# TLE9263 register map
Vendor: Infineon; File version: 0.2
Registers are 8-bit, read-write, no defined reset value unless marked. A register's access mark holds for its fields unless they carry their own. Offsets are from the block's base; [hi:lo] are bit positions; {n}, {i} and the like mark numbered series; 'fields as' and 'values as' point back to an identical list.

## CTRL — Control
Base 0x00000000
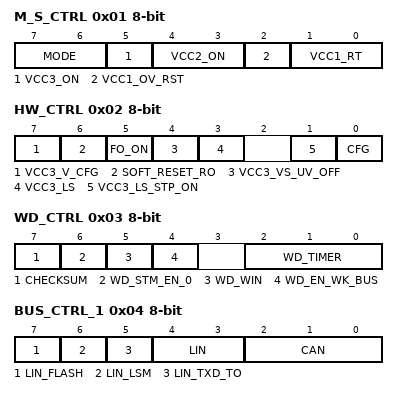
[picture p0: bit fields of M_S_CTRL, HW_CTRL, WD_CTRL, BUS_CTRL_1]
0x01 M_S_CTRL — Mode- and Supply Control
  [7:6] MODE — SBC Mode Control
    0=Normal (SBC Normal Mode); 1=Sleep (SBC Sleep Mode); 2=Stop (SBC Stop Mode); 3=Soft_Reset (SBC Reset: Soft Reset is executed (configuration of RSTN triggering in bit SOFT_RESET_RST))
  [5] VCC3_ON — VCC3 Mode Control
    0=VCC3_off; 1=VCC3_enabled (VCC3 is enabled (as independent voltage regulator))
  [4:3] VCC2_ON — VCC2 Mode Control
    0=VCC2_off; 1=Normal_Mode (VCC2 on in Normal Mode); 2=Normal_and_Stop_Mode (VCC2 on in Normal and Stop Mode); 3=VCC2 always on (except in SBC Init - if not in SBC Development Mode, SBC Restart and Fail-Safe Mode)
  [2] VCC1_OV_RST — VCC1 Over Voltage leading to Restart / Fail-Safe Mode enable
    0=off (VCC1_ OV is set in case of VCC1_OV; no SBC Restart or Fail-Safe is entered for VCC1_OV); 1=activated (VCC1_ OV is set in case of VCC1_OV; depending on the device configuration SBC Restart or SBC Fail-Safe Mode is entered (see );)
  [1:0] VCC1_RT — VCC1 Reset Threshold Control
    0=Vrt1 selected (highest threshold); 1=Vrt2 selected; 2=Vrt3 selected; 3=Vrt4 selected
0x02 HW_CTRL — Hardware Control 0
  [7] VCC3_V_CFG — VCC3 Output Voltage Configuration (if configured as independent voltage regulator)
    0=VCC3_is_same_as_VCC1 (VCC3 has same output voltage as VCC1); 1=3.3V_or_1.8V (VCC3 is configured to either 3.3V or 1.8V (depending on VCC1 derivative))
  [6] SOFT_RESET_RO — Soft Reset Configuration
    0=RO_triggered_by_Soft_Reset (RO will be triggered (pulled low) during a Soft Reset); 1=not_triggered_by_Soft_Reset (no RO trigger during a Soft Reset)
  [5] FO_ON — Failure Output Activation
    0=off (FO not activated by software, FO will be activated by specified failures (see ) (0)); 1=on (FO activated by software (via SPI), only if configured as FO (1))
  [4] VCC3_VS_UV_OFF — VCC3 VS_UV shutdown configuration
    0=VCC3_disabled_at_VS_UV (VCC3 will be disabled automatically at VS_UV); 1=VCC3_enable_below_VS_UV (VCC3 will stay enabled even below VS_UV)
  [3] VCC3_LS — VCC3 Configuration
    0=VCC3_as_stanalone_regulator (VCC3 operating as a stand-alone regulator); 1=in_load_sharing_with_VCC1 (VCC3 in load sharing operation with VCC1)
  [1] VCC3_LS_STP_ON — VCC3 Load Sharing in SBC Stop Mode configuration
    0=VCC3_in_LS_disabled (VCC3 in LS configuration during SBC Stop Mode and highpower mode: disabled); 1=VCC3_in_LS_enabled (VCC3 in LS configuration during SBC Stop Mode and highpower mode: enabled)
  [0] CFG — Configuration Select (see also )
    0=after_2nd (Depending on hardware configuration, SBC Restart or Fail-Safe Mode is reached after the 2. watchdog trigger failure (=default) - Config 3/4); 1=after_1st (Depending on hardware configuration, SBC Restart or Fail-Safe Mode is reached after the 1. watchdog trigger failure - Config 1/2)
0x03 WD_CTRL — Watchdog Control
  [7] CHECKSUM — Watchdog Setting Check Sum Bit
    0=Counts as 0 for checksum calculation; 1=Counts as 1 for checksum calculation
  [6] WD_STM_EN_0 — Watchdog Deactivation during Stop Mode, bit 0 ()
    0=active (Watchdog is active in Stop Mode); 1=off (Watchdog is deactivated in Stop Mode)
  [5] WD_WIN — Watchdog Type Selection
    0=Time-out (Watchdog works as a Time-Out watchdog); 1=Window (Watchdog works as a Window watchdog)
  [4] WD_EN_WK_BUS — Watchdog Enable after Bus (CAN) Wake in SBC Stop Mode
    0=off (Watchdog will not start after a CAN wake); 1=on (Watchdog starts with a long open window after CAN Wake)
  [2:0] WD_TIMER — Watchdog Timer Period
    0=10ms; 1=20ms; 2=50ms; 3=100ms; 4=200ms; 5=500ms; 6=1s (1000ms); 7=10s (10000ms)
0x04 BUS_CTRL_1 — Bus Control
  [7] LIN_FLASH — LIN Flash Programming Mode
    0=slope_control_active (Slope control mechanism active); 1=deactive_at_115kBaud (Deactivation of slope control for baud rates up to 115kBaud)
  [6] LIN_LSM — LIN Low-Slope Mode Selection
    0=normal_mode (LIN Normal-Mode is activated); 1=low_slope_mode (LIN Low-Slope Mode (10.4kBaud) activated)
  [5] LIN_TXD_TO — LIN TXD Time-Out Control
    0=TXD_time_out_disabled (TXD Time-Out feature disabled); 1=TXD_time_out_enabled (TXD Time-Out feature enabled)
  [4:3] LIN — LIN-Module Modes
    0=off (LIN OFF); 1=weak_capable (LIN is wake capable); 2=receive_only (LIN Receive Only Mode); 3=normal (LIN Normal Mode)
  [2:0] CAN — HS-CAN Module Modes (CAN_2 is rw type)
    0=off (CAN OFF); 1=wake_capable (CAN is wake capable (no SWK)); 2=receive_only (CAN Receive Only Mode (no SWK)); 3=normal (CAN Normal Mode (no SWK)); 4=off (CAN OFF); 5=wake_capable_(SWK) (CAN is wake capable with SWK); 6=receive_only_(SWK) (CAN Receive Only Mode with SWK); 7=normal_(SWK) (CAN Normal Mode with SWK)
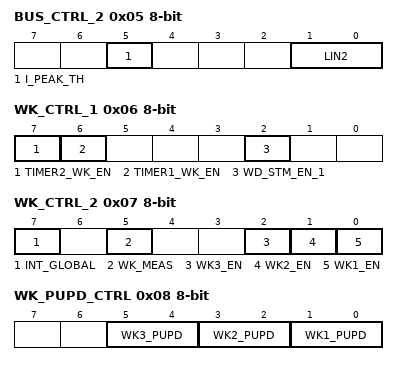
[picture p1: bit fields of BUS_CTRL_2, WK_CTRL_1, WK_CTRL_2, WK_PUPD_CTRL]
0x05 BUS_CTRL_2 — Bus Control
  [5] I_PEAK_TH — VCC1 Active Peak Threshold Selection
    0=low_active_threshold (low VCC1 active peak threshold selected (ICC1,peak_1)); 1=low_active_threshold (higher VCC1 active peak threshold selected (ICC1,peak_2))
  [1:0] LIN2 — LIN2-Module Modes
    0=off (LIN2 OFF); 1=wake_capable (LIN2 is wake capable); 2=receive_only (LIN2 Receive Only Mode); 3=normal (LIN2 Normal Mode)
0x06 WK_CTRL_1 — Internal Wake Input Control
  [7] TIMER2_WK_EN — Timer2 Wake Source Control (for cyclic wake)
    0=disabled (Timer2 wake disabled); 1=enabled (Timer2 is enabled as a wake source)
  [6] TIMER1_WK_EN — Timer1 Wake Source Control (for cyclic wake)
    values as TIMER2_WK_EN
  [2] WD_STM_EN_1 — Watchdog Deactivation during Stop Mode, bit 1 ()
    0=WD_active_in_stop_mode (Watchdog is active in Stop Mode); 1=off (Watchdog is deactivated in Stop Mode)
0x07 WK_CTRL_2 — External Wake Source Control
  [7] INT_GLOBAL — Global Interrupt Configuration (see also )
    0=wake_only (Only wake sources trigger INTN (default)); 1=all_status_bits (All status information register bits will trigger INTN (including all wake sources))
  [5] WK_MEAS — Wake / Voltage Sensing Selection (see also )
    0=Wake functionality enabled for WK; 1=Voltage sensing functionality enabled, no wake-up events are generated
  [2] WK3_EN — WK3 Wake Source Control
    0=disabled (WK3 wake disabled); 1=enabled (WK3 is enabled as a wake source)
  [1] WK2_EN — WK2 Wake Source Control
    0=disabled (WK2 wake disabled); 1=enabled (WK2 is enabled as a wake source)
  [0] WK1_EN — WK1 Wake Source Control
    0=disabled (WK1 wake disabled); 1=enabled (WK1 is enabled as a wake source)
0x08 WK_PUPD_CTRL — Wake Input Level Control
  [all] fields
    0=none (No pull-up / pull-down selected); 1=Pull-down resistor selected; 2=Pull-up resistor selected; 3=Automatic switching to pull-up or pull-down
  [5:4] WK3_PUPD — WK3 Pull-Up / Pull-Down Configuration
  [3:2] WK2_PUPD — WK2 Pull-Up / Pull-Down Configuration
  [1:0] WK1_PUPD — WK1 Pull-Up / Pull-Down Configuration
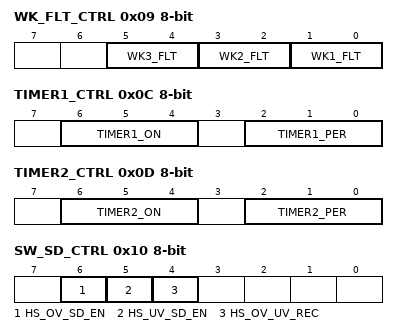
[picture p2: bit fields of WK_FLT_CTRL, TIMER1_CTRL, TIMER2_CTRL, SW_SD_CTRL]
0x09 WK_FLT_CTRL — Wake Input Filter Time Control
  [all] fields
    0=16us (Configuration A: Filter with 16μs filter time (static sensing)); 1=64us (Configuration B: Filter with 64μs filter time (static sensing)); 2=16us_Timer1 (Configuration C: Filtering at the end of the on-time; a filter time of 16μs (cyclic sensing) is selected, Timer1); 3=16us_Timer2 (Configuration D: Filtering at the end of the on-time; a filter time of 16μs (cyclic sensing) is selected, Timer2)
  [5:4] WK3_FLT — WK3 Filter Time Configuration
  [3:2] WK2_FLT — WK2 Filter Time Configuration
  [1:0] WK1_FLT — WK2 Filter Time Configuration
0x0C TIMER1_CTRL — Timer1 Control and Selection
  [6:4] TIMER1_ON — Timer1 On-Time Configuration
    0=OFF / Low (timer not running, HSx output is low); 1=0.1ms on-time; 2=0.3ms on-time; 3=1.0ms on-time; 4=10ms on-time; 5=20ms on-time; 6=OFF / HIGH (timer not running, HSx output is high)
  [2:0] TIMER1_PER — Timer1 Period Configuration
    0=10ms; 1=20ms; 2=50ms; 3=100ms; 4=200ms; 5=1s; 6=2s
0x0D TIMER2_CTRL — Timer2 Control and Selection
  [6:4] TIMER2_ON — Timer2 On-Time Configuration
    values as TIMER1_CTRL.TIMER1_ON
  [2:0] TIMER2_PER — Timer2 Period Configuration
    0=10ms; 1=20ms; 2=50ms; 3=100ms; 4=200ms; 5=1s; 6=2s
0x10 SW_SD_CTRL — Switch Shutdown Control
  [6] HS_OV_SD_EN — Shutdown Disabling of HS1...4 in case of VSHS OV
    0=shutdown enabled in case of VSHS OV; 1=shutdown disabled in case of VSHS OV
  [5] HS_UV_SD_EN — Shutdown Disabling of HS1...4 in case of VSHS UV
    0=shutdown enabled in case of VSHS UV; 1=shutdown disabled in case of VSHS UV
  [4] HS_OV_UV_REC — Switch Recovery after Removal of VSHS OV/UV for HS1...4
    0=Switch_recovery_disabled (Switch recovery is disabled); 1=Previous_state_enabled (Previous state before VSHS OV/UV is enabled after OV/UV condition is removed)
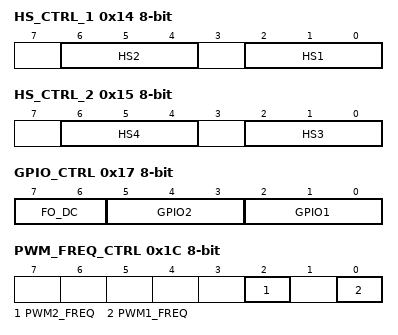
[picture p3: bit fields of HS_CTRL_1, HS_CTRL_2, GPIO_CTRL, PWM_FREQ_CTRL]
0x14 HS_CTRL_1 — High-Side Switch Control 1
  [6:4] HS2 — HS2 Configuration
    0=Off; 1=On; 2=Controlled_by_Timer1; 3=Controlled_by_Timer2; 4=Controlled_by_PWM1; 5=Controlled_by_PWM2
  [2:0] HS1 — HS1 Configuration
    values as HS2
0x15 HS_CTRL_2 — High-Side Switch Control 2
  [6:4] HS4 — HS4 Configuration
    values as HS_CTRL_1.HS2
  [2:0] HS3 — HS3 Configuration
    values as HS_CTRL_1.HS2
0x17 GPIO_CTRL — GPIO Configuration Control
  [7:6] FO_DC — Duty Cycle Configuration of FO3 (if selected)
    0=20%; 1=10%; 2=5%; 3=2.5%
  [5:3] GPIO2 — GPIO2 Configuration
    {v}=FO3 (FO3 selected) (v=0..3); 4=OFF; 5=Wake input enabled (16us static filter); 6=Low-Side_PWM (Low-Side Switch ON); 7=High-Side_PWM (High-Side Switch ON)
  [2:0] GPIO1 — GPIO1 Configuration
    {v}=FO2 (FO2 selected) (v=0..3); 4=OFF; 5=Wake input enabled (16us static filter); 6=Low-Side_PWM (Low-Side Switch ON); 7=High-Side_PWM (High-Side Switch ON)
0x18 PWM1_CTRL — PWM1 Configuration Control
  [7:0] PWM1_DC — PWM1 Duty Cycle (bit0=LSB; bit7=MSB)
0x19 PWM2_CTRL — PWM2 Configuration Control
  [7:0] PWM2_DC — PWM2 Duty Cycle (bit0=LSB; bit7=MSB)
0x1C PWM_FREQ_CTRL — PWM Frequency Configuration Control
  [2] PWM2_FREQ — PWM2 Frequency Selection
    0=200Hz configuration; 1=400Hz configuration
  [0] PWM1_FREQ — PWM1 Frequency Selection
    0=200Hz configuration; 1=400Hz configuration
0x1E SYS_STATUS_CTRL — System Status Control
  [7:0] SYS_STAT — System Status Control Byte (bit0=LSB; bit7=MSB)
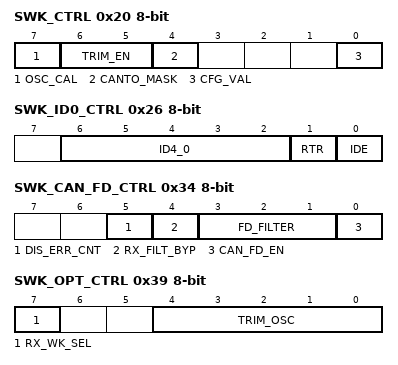
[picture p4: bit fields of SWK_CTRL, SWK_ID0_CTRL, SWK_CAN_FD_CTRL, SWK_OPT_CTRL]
0x20 SWK_CTRL — CAN Selective Wake Control
  [7] OSC_CAL — Oscillator Calibration Mode
    0=disabled (Oscillator Calibration is disabled); 1=enabled (Oscillator Calibration is enabled)
  [6:5] TRIM_EN — (Un)locking mechanism of oscillator recalibration
    0=locked_0; 1=locked_1; 2=locked_2; 3=unlocked
  [4] CANTO_MASK — CAN Time Out Masking
    0=no_INTN (CAN time-out is masked - no interrupt (on pin INTN) is triggered); 1=INTN (CAN time-out is signaled on INTN)
  [0] CFG_VAL — SWK Configuration valid
    0=not_valid (Configuration is not valid (SWK not possible)); 1=valid (SWK configuration valid, needs to be set to enable SWK)
0x21 SWK_BTL0_CTRL — SWK Bit Timing Logic Control1
  [7:0] TBIT — Number of Time Quanta in a Bit Time
0x22 SWK_BTL1_CTRL — SWK Bit Timing Control2
  [5:0] SP — Sampling Point Position
0x23 SWK_ID3_CTRL — SWK WUF Identifier bits 28...21
  [7:0] ID28_21 — WUF Identifier Bits 28...21
0x24 SWK_ID2_CTRL — SWK WUF Identifier bits 20...13
  [7:0] ID20_13 — WUF Identifier Bits 20...13
0x25 SWK_ID1_CTRL — SWK WUF Identifier bits 12...5
  [7:0] ID12_5 — WUF Identifier Bits 12...5
0x26 SWK_ID0_CTRL — SWK WUF Identifier bits 4...0
  [6:2] ID4_0 — WUF Identifier Bits 4..0
  [1] RTR — Remote Transmission Request Field (acc. ISO 11898-1)
    0=disabled (Normal Data Frame); 1=enabled (Remote Transmission Request)
  [0] IDE — Identifier Extension Bit
    0=11bit (Standard Identifier Length (11 bit)); 1=29bit (Extended Identifier Length (29 bit))
0x27 SWK_MASK_ID3_CTRL — SWK WUF Identifier Mask bits 28...21
  [7:0] MASK_ID28_21 — WUF Identifier Mask Bits 28...21
    0=ignored (Unmasked - bit is ignored); 1=enabled (Masked - bit is compared in CAN frame)
0x28 SWK_MASK_ID2_CTRL — SWK WUF Identifier Mask bits 20...13
  [7:0] MASK_ID20_13 — WUF Identifier Mask Bits 20...13
    values as SWK_MASK_ID3_CTRL.MASK_ID28_21
0x29 SWK_MASK_ID1_CTRL — SWK WUF Identifier Mask bits 12...5
  [7:0] MASK_ID12_5 — WUF Identifier Mask Bits 12...5
    values as SWK_MASK_ID3_CTRL.MASK_ID28_21
0x2A SWK_MASK_ID0_CTRL — SWK WUF Identifier bits 4...0
  [6:2] MASK_ID4_0 — WUF Identifier MASK Bits 4..0
    0=irgnored (Unmasked - bit is ignored); 1=enabled (Masked - bit is compared in CAN frame)
0x2B SWK_DLC_CTRL — SWK Frame Data Length Code Control
  [3:0] DLC — Payload length in number of bytes
    0=Frame Data Length = 0 or cleared; {v}=Frame Data Length = {v} (v=1..8)
0x2C SWK_DATA7_CTRL — SWK Data7 Register
  [7:0] DATA7 — Data7 byte content(bit0=LSB; bit7=MSB)
0x2D SWK_DATA6_CTRL — SWK Data6 Register
  [7:0] DATA6 — Data6 byte content (bit0=LSB; bit7=MSB)
0x2E SWK_DATA5_CTRL — SWK Data5 Register
  [7:0] DATA5 — Data5 byte content (bit0=LSB; bit7=MSB)
0x2F SWK_DATA4_CTRL — SWK Data4 Register
  [7:0] DATA4 — Data4 byte content (bit0=LSB; bit7=MSB)
0x30 SWK_DATA3_CTRL — SWK Data3 Register
  [7:0] DATA3 — Data3 byte content (bit0=LSB; bit7=MSB)
0x31 SWK_DATA2_CTRL — SWK Data2 Register
  [7:0] DATA2 — Data2 byte content (bit0=LSB; bit7=MSB)
0x32 SWK_DATA1_CTRL — SWK Data1 Register
  [7:0] DATA1 — Data1 byte content (bit0=LSB; bit7=MSB)
0x33 SWK_DATA0_CTRL — SWK Data0 Register
  [7:0] DATA0 — Data0 byte content (bit0=LSB; bit7=MSB)
0x34 SWK_CAN_FD_CTRL — CAN FD Configuration Control Register
  [5] DIS_ERR_CNT — Error Counter Disable Function
    0=counter_enabled (Error Counter is enabled during SWK); 1=counter_disabled (Error counter is disabled during SWK only if CAN_FD_EN = ‘1')
  [4] RX_FILT_BYP — RX Receiver Filter Bypass
    0=disabled (RX Filter not bypassed); 1=enabled (RX Filter bypassed)
  [3:1] FD_FILTER — CAN FD Dominant Filter Time
    0=50ns; 1=100ns; 2=150ns; 3=200ns; 4=250ns; 5=300ns; 6=350ns; 7=700ns
  [0] CAN_FD_EN — CAN FD Tolerant Mode
    0=disabled (CAN FD Tolerant Mode disabled); 1=enabled (CAN FD Tolerant Mode enabled)
0x38 SWK_OSC_TRIM_CTRL — SWK Oscillator Trimming Register
  [7:0] TRIM_OSC — Oscillator trimming (bit0=LSB; bit7=MSB); (only writable if TRIM_EN = ‘11')
0x39 SWK_OPT_CTRL — Selective Wake Options Register
  [7] RX_WK_SEL — SWK Receiver selection (only accessible if TRIM_EN = ‘11')
    0=Low-Power Receiver selected during SWK; 1=Standard Receiver selected during SWK
  [4:0] TRIM_OSC — Oscillator trimming (bit8=LSB; bit12=MSB); (only writable if TRIM_EN = ‘11')
0x3A SWK_OSC_CAL_H_STAT ro — SWK Oscillator Calibration High Register
  [7:0] OSC_CAL_H — Oscillator Calibration High Register
0x3B SWK_OSC_CAL_L_STAT ro — SWK Oscillator Calibration Low Register
  [7:0] OSC_CAL_L — Oscillator Calibration Low Register
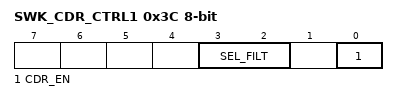
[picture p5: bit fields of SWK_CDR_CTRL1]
0x3C SWK_CDR_CTRL1 — CDR Control 1 Register
  [3:2] SEL_FILT — Select Time Constant of Filter
    0=Time constant 8; 1=16(default) (Time constant 16 (default)); 2=Time constant 32; 3=adaptive (adapt distance between falling edges 2, 3 bit: Time constant 32 distance between f. edges 4, 5, 6, 7, 8 bit: Time constant 16 distance between falling edges 9, 10 bit: Time constant 8)
  [0] CDR_EN — Enable CDR
    0=disabled (CDR disabled); 1=enabled (CDR enabled)
0x3D SWK_CDR_CTRL2 — CDR Control 2Register
  [1:0] SEL_OSC_CLK — Input Frequency for CDR module
0x3E SWK_CDR_LIMIT_HIGH_CTRL — SWK CDR Upper Limit Control
  [7:0] CDR_LIM_H — Upper Bit Time Detection Range of Clock and Data Recovery
0x3F SWK_CDR_LIMIT_LOW_CTRL — SWK CDR Lower Limit Control
  [7:0] CDR_LIM_L — Lower Bit Time Detection Range of Clock and Data Recovery
